VERSION ""

NS_ :

BS_:

BU_:
VAL_TABLE_ ChargerStatus1_CHARGER_STATUS 1 "IDLE" 2 "CHARGE" 3 "RECOVERABLE_ERROR" 4 "NONRECOVERABLE_ERROR" ;
VAL_TABLE_ ChargerErrorsWarnings_DCOVS 0 "LO" 1 "HI" ;
VAL_TABLE_ ChargerErrorsWarnings_SCICOMMFAIL 0 "LO" 1 "HI" ;
VAL_TABLE_ ChargerErrorsWarnings_HIGHMAINS 0 "LO" 1 "HI" ;
VAL_TABLE_ ChargerErrorsWarnings_LOWMAINS 0 "LO" 1 "HI" ;
VAL_TABLE_ ChargerErrorsWarnings_HIGHTEMP 0 "LO" 1 "HI" ;
VAL_TABLE_ ChargerErrorsWarnings_LOWTEMP 0 "LO" 1 "HI" ;
VAL_TABLE_ ChargerErrorsWarnings_CURRLIM 0 "LO" 1 "HI" ;
VAL_TABLE_ ChargerErrorsWarnings_MODFAIL 0 "LO" 1 "HI" ;
VAL_TABLE_ ChargerErrorsWarnings_DCUVS 0 "LO" 1 "HI" ;
VAL_TABLE_ ChargerErrorsWarnings_CNTCOMMFAIL 0 "LO" 1 "HI" ;

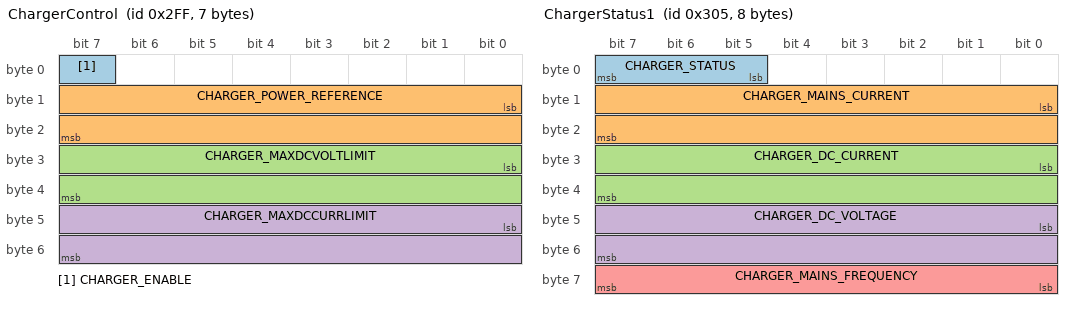
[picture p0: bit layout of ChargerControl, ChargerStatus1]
BO_ 767 ChargerControl: 7 Vector__XXX
 SG_ CHARGER_ENABLE : 7|1@1+ (1,0) [0|0] "" Vector__XXX
 SG_ CHARGER_POWER_REFERENCE : 8|16@1+ (1,0) [0|0] "" Vector__XXX
 SG_ CHARGER_MAXDCVOLTLIMIT : 24|16@1+ (1,0) [0|0] "" Vector__XXX
 SG_ CHARGER_MAXDCCURRLIMIT : 40|16@1+ (1,0) [0|0] "" Vector__XXX

BO_ 773 ChargerStatus1: 8 Vector__XXX
 SG_ CHARGER_STATUS : 5|3@1+ (1,0) [0|0] "" Vector__XXX
 SG_ CHARGER_MAINS_CURRENT : 8|16@1+ (1,0) [0|0] "" Vector__XXX
 SG_ CHARGER_DC_CURRENT : 24|16@1+ (1,0) [0|0] "" Vector__XXX
 SG_ CHARGER_DC_VOLTAGE : 40|16@1+ (1,0) [0|0] "" Vector__XXX
 SG_ CHARGER_MAINS_FREQUENCY : 56|8@1+ (1,0) [0|0] "" Vector__XXX

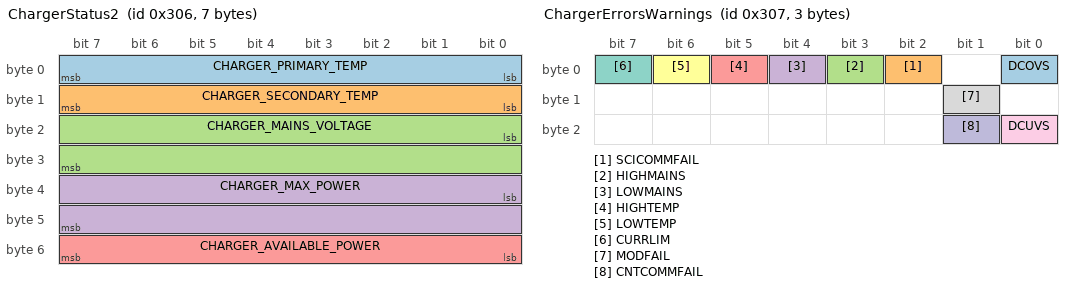
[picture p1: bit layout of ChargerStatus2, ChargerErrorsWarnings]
BO_ 774 ChargerStatus2: 7 Vector__XXX
 SG_ CHARGER_PRIMARY_TEMP : 0|8@1- (1,0) [0|0] "" Vector__XXX
 SG_ CHARGER_SECONDARY_TEMP : 8|8@1- (1,0) [0|0] "" Vector__XXX
 SG_ CHARGER_MAINS_VOLTAGE : 16|16@1+ (1,0) [0|0] "" Vector__XXX
 SG_ CHARGER_MAX_POWER : 32|16@1+ (1,0) [0|0] "" Vector__XXX
 SG_ CHARGER_AVAILABLE_POWER : 48|8@1+ (1,0) [0|0] "" Vector__XXX

BO_ 775 ChargerErrorsWarnings: 3 Vector__XXX
 SG_ DCOVS : 0|1@1+ (1,0) [0|0] "" Vector__XXX
 SG_ SCICOMMFAIL : 2|1@1+ (1,0) [0|0] "" Vector__XXX
 SG_ HIGHMAINS : 3|1@1+ (1,0) [0|0] "" Vector__XXX
 SG_ LOWMAINS : 4|1@1+ (1,0) [0|0] "" Vector__XXX
 SG_ HIGHTEMP : 5|1@1+ (1,0) [0|0] "" Vector__XXX
 SG_ LOWTEMP : 6|1@1+ (1,0) [0|0] "" Vector__XXX
 SG_ CURRLIM : 7|1@1+ (1,0) [0|0] "" Vector__XXX
 SG_ MODFAIL : 9|1@1+ (1,0) [0|0] "" Vector__XXX
 SG_ DCUVS : 16|1@1+ (1,0) [0|0] "" Vector__XXX
 SG_ CNTCOMMFAIL : 17|1@1+ (1,0) [0|0] "" Vector__XXX

BO_ 776 ChargerSerialNumber: 8 Vector__XXX
 SG_ CHARGER_SERIALNUMBER : 0|48@1+ (1,0) [0|0] "" Vector__XXX
 SG_ CHARGER_BASE_CANIDENTIFIER : 48|16@1+ (1,0) [0|0] "" Vector__XXX

BA_DEF_  "BusType" STRING ;
BA_DEF_DEF_  "BusType" "CAN";
VAL_ 773 CHARGER_STATUS 1 "IDLE" 2 "CHARGE" 3 "RECOVERABLE_ERROR" 4 "NONRECOVERABLE_ERROR" ;
VAL_ 775 DCOVS 0 "LO" 1 "HI" ;
VAL_ 775 SCICOMMFAIL 0 "LO" 1 "HI" ;
VAL_ 775 HIGHMAINS 0 "LO" 1 "HI" ;
VAL_ 775 LOWMAINS 0 "LO" 1 "HI" ;
VAL_ 775 HIGHTEMP 0 "LO" 1 "HI" ;
VAL_ 775 LOWTEMP 0 "LO" 1 "HI" ;
VAL_ 775 CURRLIM 0 "LO" 1 "HI" ;
VAL_ 775 MODFAIL 0 "LO" 1 "HI" ;
VAL_ 775 DCUVS 0 "LO" 1 "HI" ;
VAL_ 775 CNTCOMMFAIL 0 "LO" 1 "HI" ;
